# EFM32TG11B320F128GQ48 register map
File version: 5.8.2
CPU: CM0PLUS r0p1, little endian, MPU, no FPU, 3 interrupt priority bits
Registers are 32-bit, read-write, reset 0x0 unless marked. A register's access mark holds for its fields unless they carry their own. Offsets are from the block's base; [hi:lo] are bit positions; {n}, {i} and the like mark numbered series.

## SMU
Base 0x40020000
0x0C IF ro — Interrupt Flag Register
  [0] PPUPRIV — PPU Privilege Interrupt Flag
0x10 IFS wo — Interrupt Flag Set Register
  [0] PPUPRIV — Set PPUPRIV Interrupt Flag
0x14 IFC wo — Interrupt Flag Clear Register
  [0] PPUPRIV — Clear PPUPRIV Interrupt Flag
0x18 IEN — Interrupt Enable Register
  [0] PPUPRIV — PPUPRIV Interrupt Enable
0x40 PPUCTRL — PPU Control Register
  [0] ENABLE
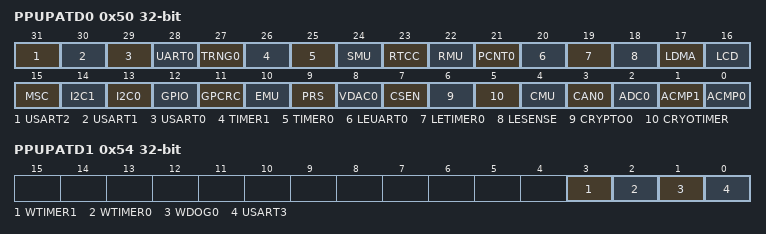
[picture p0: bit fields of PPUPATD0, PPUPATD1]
0x50 PPUPATD0 — PPU Privilege Access Type Descriptor 0
  [31] USART2 — Universal Synchronous/Asynchronous Receiver/Transmitter 2 access control bit
  [30] USART1 — Universal Synchronous/Asynchronous Receiver/Transmitter 1 access control bit
  [29] USART0 — Universal Synchronous/Asynchronous Receiver/Transmitter 0 access control bit
  [28] UART0 — Universal Asynchronous Receiver/Transmitter 0 access control bit
  [27] TRNG0 — True Random Number Generator 0 access control bit
  [26] TIMER1 — Timer 1 access control bit
  [25] TIMER0 — Timer 0 access control bit
  [24] SMU — Security Management Unit access control bit
  [23] RTCC — Real-Time Counter and Calendar access control bit
  [22] RMU — Reset Management Unit access control bit
  [21] PCNT0 — Pulse Counter 0 access control bit
  [20] LEUART0 — Low Energy UART 0 access control bit
  [19] LETIMER0 — Low Energy Timer 0 access control bit
  [18] LESENSE — Low Energy Sensor Interface access control bit
  [17] LDMA — Linked Direct Memory Access Controller access control bit
  [16] LCD — Liquid Crystal Display Controller access control bit
  [15] MSC — Memory System Controller access control bit
  [14] I2C1 — I2C 1 access control bit
  [13] I2C0 — I2C 0 access control bit
  [12] GPIO — General purpose Input/Output access control bit
  [11] GPCRC — General Purpose CRC access control bit
  [10] EMU — Energy Management Unit access control bit
  [9] PRS — Peripheral Reflex System access control bit
  [8] VDAC0 — Digital to Analog Converter 0 access control bit
  [7] CSEN — Capacitive touch sense module access control bit
  [6] CRYPTO0 — Advanced Encryption Standard Accelerator access control bit
  [5] CRYOTIMER — CRYOTIMER access control bit
  [4] CMU — Clock Management Unit access control bit
  [3] CAN0 — CAN 0 access control bit
  [2] ADC0 — Analog to Digital Converter 0 access control bit
  [1] ACMP1 — Analog Comparator 1 access control bit
  [0] ACMP0 — Analog Comparator 0 access control bit
0x54 PPUPATD1 — PPU Privilege Access Type Descriptor 1
  [3] WTIMER1 — Wide Timer 1 access control bit
  [2] WTIMER0 — Wide Timer 0 access control bit
  [1] WDOG0 — Watchdog access control bit
  [0] USART3 — Universal Synchronous/Asynchronous Receiver/Transmitter 3 access control bit
0x90 PPUFS ro — PPU Fault Status
  [6:0] PERIPHID
    0=ACMP0 (Analog Comparator 0); 1=ACMP1 (Analog Comparator 1); 2=ADC0 (Analog to Digital Converter 0); 3=CAN0; 4=CMU (Clock Management Unit); 5=CRYOTIMER; 6=CRYPTO0 (Advanced Encryption Standard Accelerator); 7=CSEN (Capacitive touch sense module); 8=VDAC0 (Digital to Analog Converter 0); 9=PRS (Peripheral Reflex System); 10=EMU (Energy Management Unit); 11=GPCRC (General Purpose CRC); 12=GPIO (General purpose Input/Output); 13=I2C0; 14=I2C1; 15=MSC (Memory System Controller); 16=LCD (Liquid Crystal Display Controller); 17=LDMA (Linked Direct Memory Access Controller); 18=LESENSE (Low Energy Sensor Interface); 19=LETIMER0 (Low Energy Timer 0); 20=LEUART0 (Low Energy UART 0); 21=PCNT0 (Pulse Counter 0); 22=RMU (Reset Management Unit); 23=RTCC (Real-Time Counter and Calendar); 24=SMU (Security Management Unit); 25=TIMER0; 26=TIMER1; 27=TRNG0 (True Random Number Generator 0); 28=UART0 (Universal Asynchronous Receiver/Transmitter 0); {v}=USART{v-29} (Universal Synchronous/Asynchronous Receiver/Transmitter {v-29}) (v=29..32); 33=WDOG0 (Watchdog); 34=WTIMER0 (Wide Timer 0); 35=WTIMER1 (Wide Timer 1)

## Notices in the file
# License
Copyright 2019 Silicon Laboratories Inc. www.silabs.com
SPDX-License-Identifier: Zlib
The licensor of this software is Silicon Laboratories Inc.
This software is provided 'as-is', without any express or implied
warranty. In no event will the authors be held liable for any damages
arising from the use of this software.
Permission is granted to anyone to use this software for any purpose,
including commercial applications, and to alter it and redistribute it
freely, subject to the following restrictions:
1. The origin of this software must not be misrepresented; you must not
claim that you wrote the original software. If you use this software
in a product, an acknowledgment in the product documentation would be
appreciated but is not required.
2. Altered source versions must be plainly marked as such, and must not be
misrepresented as being the original software.
3. This notice may not be removed or altered from any source distribution.
